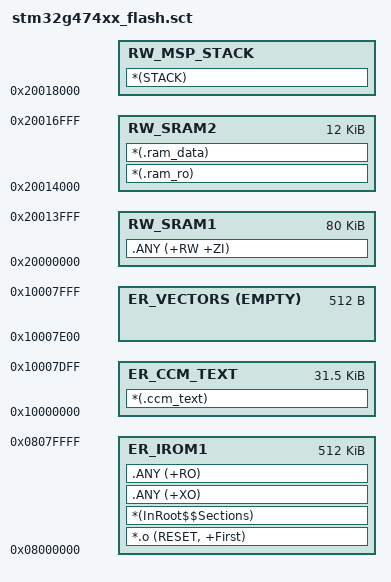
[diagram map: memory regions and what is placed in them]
; ============================================================================
; ⚠️ 仅作参考 / REFERENCE ONLY —— 不属于 PowerControl 目录
; 来源: NUEDC_2026A/Firmware_0/MDK-ARM/stm32g474xx_flash.sct (STM32G474, Keil 分散加载)
; 在此的原因: 它给出「代码/向量表/快速变量分别落到 CCM SRAM 与 SRAM2」的具体分区，
;            是本工程 RAM 执行优化实践的对照样例，需与 stm32g4xx_it.c 配套阅读。
; 为什么不该留在这里: 链接脚本属于 MDK-ARM/ 与本板内存布局, G071 也没有 CCM SRAM。
; 移植做法: 按 README_RAM_EXEC.md 改写本工程 MDK-ARM/Ld/*.sct, 然后删除本文件。
; ============================================================================

LR_IROM1 0x8000000 0x00080000  {  ; load_region size_region
  ER_IROM1 0x8000000 0x00080000  {  ; load address = excetion address
   *.o (RESET, +First)
   *(InRoot$$Sections)
   .ANY (+XO)
   .ANY (+RO)
  }
;***region***;
;***endregion***;
  
  ; 高频执行的程序，放在CCM SRAM(31KB)
  ER_CCM_TEXT 0x10000000 0x00007E00  {
    *(.ccm_text)
  }
  ; 中断向量表512B，也放在CCM SRAM
  ER_VECTORS 0x10007E00 EMPTY 0x00000200 {
  }

  ; 其他变量放在SRAM1(80KB)
  RW_SRAM1 0x20000000 0x00014000  {
    .ANY (+RW +ZI)
  }
  ; 快速变量和常量池放在SRAM2(12KB)
  RW_SRAM2 0x20014000 0x0003000  {
    *(.ram_ro)
    *(.ram_data)     
  }
  ; 主堆栈4KB，从SRAM2顶部向下生长
  RW_MSP_STACK 0x20018000 -0x00001000 {
    *(STACK)
  }
  
  ; 通过填充FLASH空区域确定最大容量
  ; END_OF_BLOCK (0x08080000) FIXED EMPTY 0x0{}
}


/*-Start of  regions- Auto-generated By STM32CubeMX-*/
